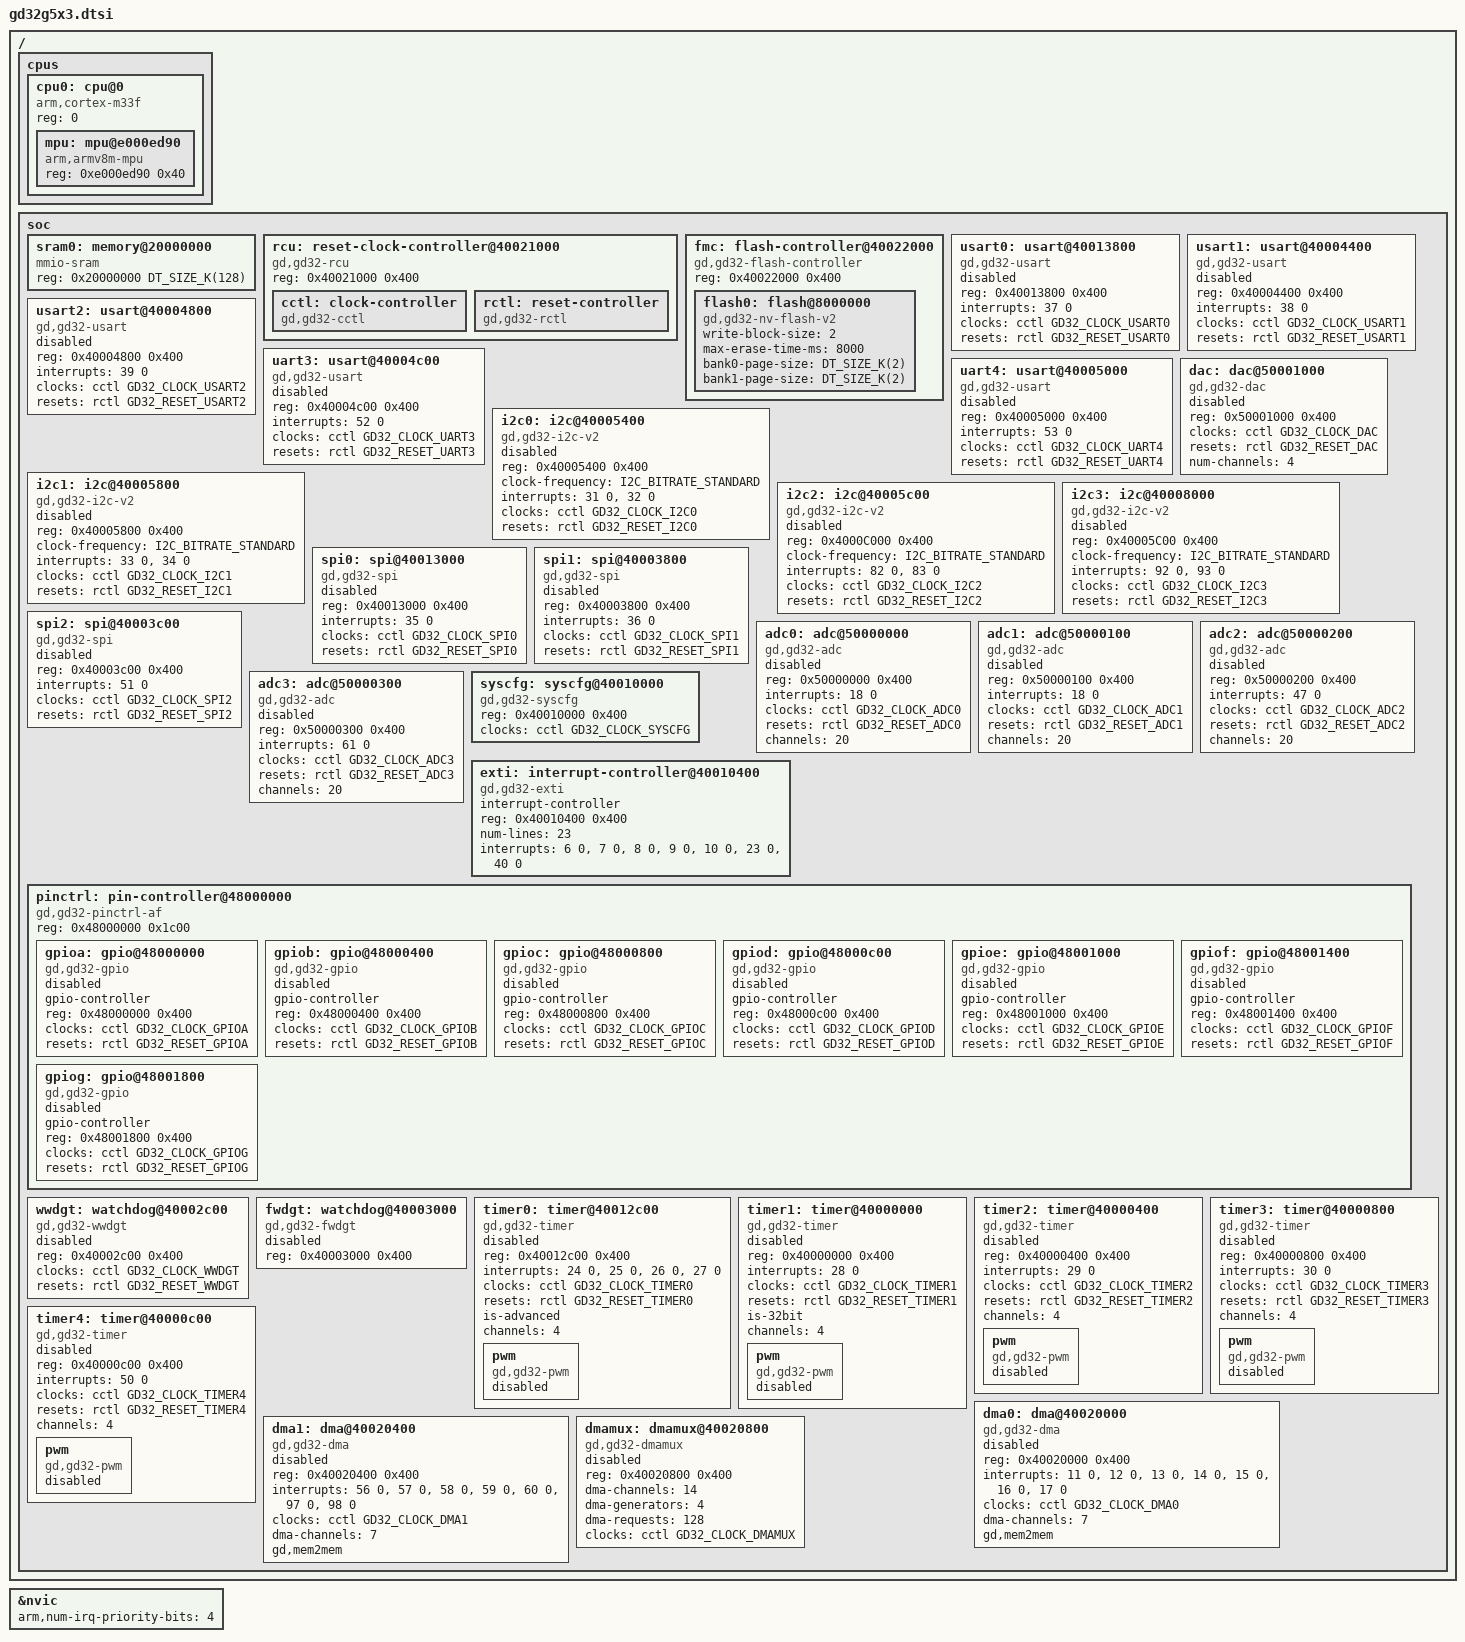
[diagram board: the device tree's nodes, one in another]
/*
 * Copyright (c) 2026 GigaDevice Semiconductor Inc.
 *
 * SPDX-License-Identifier: Apache-2.0
 */

#include <arm/armv8-m.dtsi>
#include <zephyr/dt-bindings/adc/adc.h>
#include <zephyr/dt-bindings/gpio/gpio.h>
#include <zephyr/dt-bindings/i2c/i2c.h>
#include <zephyr/dt-bindings/pwm/pwm.h>
#include <zephyr/dt-bindings/clock/gd32g5x3-clocks.h>
#include <zephyr/dt-bindings/reset/gd32g5x3.h>

/ {
	cpus {
		#address-cells = <1>;
		#size-cells = <0>;

		cpu0: cpu@0 {
			compatible = "arm,cortex-m33f";
			reg = <0>;
			#address-cells = <1>;
			#size-cells = <1>;

			mpu: mpu@e000ed90 {
				compatible = "arm,armv8m-mpu";
				reg = <0xe000ed90 0x40>;
			};
		};
	};

	soc {
		sram0: memory@20000000 {
			compatible = "mmio-sram";
			reg = <0x20000000 DT_SIZE_K(128)>;
		};

		rcu: reset-clock-controller@40021000 {
			compatible = "gd,gd32-rcu";
			reg = <0x40021000 0x400>;
			status = "okay";

			cctl: clock-controller {
				compatible = "gd,gd32-cctl";
				#clock-cells = <1>;
				status = "okay";
			};

			rctl: reset-controller {
				compatible = "gd,gd32-rctl";
				#reset-cells = <1>;
				status = "okay";
			};
		};

		fmc: flash-controller@40022000 {
			compatible = "gd,gd32-flash-controller";
			reg = <0x40022000 0x400>;

			#address-cells = <1>;
			#size-cells = <1>;

			flash0: flash@8000000 {
				compatible = "gd,gd32-nv-flash-v2", "soc-nv-flash";
				write-block-size = <2>;
				max-erase-time-ms = <8000>;
				/* G5x3: dual-bank, page size 2KB in single-bank mode */
				bank0-page-size = <DT_SIZE_K(2)>;
				bank1-page-size = <DT_SIZE_K(2)>;
			};
		};

		usart0: usart@40013800 {
			compatible = "gd,gd32-usart";
			reg = <0x40013800 0x400>;
			interrupts = <37 0>;
			clocks = <&cctl GD32_CLOCK_USART0>;
			resets = <&rctl GD32_RESET_USART0>;
			status = "disabled";
		};

		usart1: usart@40004400 {
			compatible = "gd,gd32-usart";
			reg = <0x40004400 0x400>;
			interrupts = <38 0>;
			clocks = <&cctl GD32_CLOCK_USART1>;
			resets = <&rctl GD32_RESET_USART1>;
			status = "disabled";
		};

		usart2: usart@40004800 {
			compatible = "gd,gd32-usart";
			reg = <0x40004800 0x400>;
			interrupts = <39 0>;
			clocks = <&cctl GD32_CLOCK_USART2>;
			resets = <&rctl GD32_RESET_USART2>;
			status = "disabled";
		};

		uart3: usart@40004c00 {
			compatible = "gd,gd32-usart";
			reg = <0x40004c00 0x400>;
			interrupts = <52 0>;
			clocks = <&cctl GD32_CLOCK_UART3>;
			resets = <&rctl GD32_RESET_UART3>;
			status = "disabled";
		};

		uart4: usart@40005000 {
			compatible = "gd,gd32-usart";
			reg = <0x40005000 0x400>;
			interrupts = <53 0>;
			clocks = <&cctl GD32_CLOCK_UART4>;
			resets = <&rctl GD32_RESET_UART4>;
			status = "disabled";
		};

		dac: dac@50001000 {
			compatible = "gd,gd32-dac";
			reg = <0x50001000 0x400>;
			clocks = <&cctl GD32_CLOCK_DAC>;
			resets = <&rctl GD32_RESET_DAC>;
			num-channels = <4>;
			status = "disabled";
			#io-channel-cells = <1>;
		};

		i2c0: i2c@40005400 {
			compatible = "gd,gd32-i2c-v2";
			reg = <0x40005400 0x400>;
			#address-cells = <1>;
			#size-cells = <0>;
			clock-frequency = <I2C_BITRATE_STANDARD>;
			interrupts = <31 0>, <32 0>;
			interrupt-names = "event", "error";
			clocks = <&cctl GD32_CLOCK_I2C0>;
			resets = <&rctl GD32_RESET_I2C0>;
			status = "disabled";
		};

		i2c1: i2c@40005800 {
			compatible = "gd,gd32-i2c-v2";
			reg = <0x40005800 0x400>;
			#address-cells = <1>;
			#size-cells = <0>;
			clock-frequency = <I2C_BITRATE_STANDARD>;
			interrupts = <33 0>, <34 0>;
			interrupt-names = "event", "error";
			clocks = <&cctl GD32_CLOCK_I2C1>;
			resets = <&rctl GD32_RESET_I2C1>;
			status = "disabled";
		};

		i2c2: i2c@40005c00 {
			compatible = "gd,gd32-i2c-v2";
			reg = <0x4000C000 0x400>;
			#address-cells = <1>;
			#size-cells = <0>;
			clock-frequency = <I2C_BITRATE_STANDARD>;
			interrupts = <82 0>, <83 0>;
			interrupt-names = "event", "error";
			clocks = <&cctl GD32_CLOCK_I2C2>;
			resets = <&rctl GD32_RESET_I2C2>;
			status = "disabled";
		};

		i2c3: i2c@40008000 {
			compatible = "gd,gd32-i2c-v2";
			reg = <0x40005C00 0x400>;
			#address-cells = <1>;
			#size-cells = <0>;
			clock-frequency = <I2C_BITRATE_STANDARD>;
			interrupts = <92 0>, <93 0>;
			interrupt-names = "event", "error";
			clocks = <&cctl GD32_CLOCK_I2C3>;
			resets = <&rctl GD32_RESET_I2C3>;
			status = "disabled";
		};

		spi0: spi@40013000 {
			compatible = "gd,gd32-spi";
			reg = <0x40013000 0x400>;
			interrupts = <35 0>;
			clocks = <&cctl GD32_CLOCK_SPI0>;
			resets = <&rctl GD32_RESET_SPI0>;
			#address-cells = <1>;
			#size-cells = <0>;
			status = "disabled";
		};

		spi1: spi@40003800 {
			compatible = "gd,gd32-spi";
			reg = <0x40003800 0x400>;
			interrupts = <36 0>;
			clocks = <&cctl GD32_CLOCK_SPI1>;
			resets = <&rctl GD32_RESET_SPI1>;
			#address-cells = <1>;
			#size-cells = <0>;
			status = "disabled";
		};

		spi2: spi@40003c00 {
			compatible = "gd,gd32-spi";
			reg = <0x40003c00 0x400>;
			interrupts = <51 0>;
			clocks = <&cctl GD32_CLOCK_SPI2>;
			resets = <&rctl GD32_RESET_SPI2>;
			#address-cells = <1>;
			#size-cells = <0>;
			status = "disabled";
		};

		adc0: adc@50000000 {
			compatible = "gd,gd32-adc";
			reg = <0x50000000 0x400>;
			interrupts = <18 0>;
			clocks = <&cctl GD32_CLOCK_ADC0>;
			resets = <&rctl GD32_RESET_ADC0>;
			channels = <20>;
			#io-channel-cells = <1>;
			status = "disabled";
		};

		adc1: adc@50000100 {
			compatible = "gd,gd32-adc";
			reg = <0x50000100 0x400>;
			interrupts = <18 0>;
			clocks = <&cctl GD32_CLOCK_ADC1>;
			resets = <&rctl GD32_RESET_ADC1>;
			channels = <20>;
			#io-channel-cells = <1>;
			status = "disabled";
		};

		adc2: adc@50000200 {
			compatible = "gd,gd32-adc";
			reg = <0x50000200 0x400>;
			interrupts = <47 0>;
			clocks = <&cctl GD32_CLOCK_ADC2>;
			resets = <&rctl GD32_RESET_ADC2>;
			channels = <20>;
			#io-channel-cells = <1>;
			status = "disabled";
		};

		adc3: adc@50000300 {
			compatible = "gd,gd32-adc";
			reg = <0x50000300 0x400>;
			interrupts = <61 0>;
			clocks = <&cctl GD32_CLOCK_ADC3>;
			resets = <&rctl GD32_RESET_ADC3>;
			channels = <20>;
			#io-channel-cells = <1>;
			status = "disabled";
		};

		syscfg: syscfg@40010000 {
			compatible = "gd,gd32-syscfg";
			reg = <0x40010000 0x400>;
			clocks = <&cctl GD32_CLOCK_SYSCFG>;
		};

		exti: interrupt-controller@40010400 {
			compatible = "gd,gd32-exti";
			interrupt-controller;
			#interrupt-cells = <1>;
			#address-cells = <0>;
			reg = <0x40010400 0x400>;
			num-lines = <23>;
			interrupts = <6 0>, <7 0>, <8 0>, <9 0>,
					<10 0>, <23 0>, <40 0>;
			interrupt-names = "line0", "line1", "line2", "line3",
					"line4", "line5-9", "line10-15";
		};

		pinctrl: pin-controller@48000000 {
			compatible = "gd,gd32-pinctrl-af";
			reg = <0x48000000 0x1c00>;
			#address-cells = <1>;
			#size-cells = <1>;
			status = "okay";

			gpioa: gpio@48000000 {
				compatible = "gd,gd32-gpio";
				gpio-controller;
				#gpio-cells = <2>;
				reg = <0x48000000 0x400>;
				clocks = <&cctl GD32_CLOCK_GPIOA>;
				resets = <&rctl GD32_RESET_GPIOA>;
				status = "disabled";
			};

			gpiob: gpio@48000400 {
				compatible = "gd,gd32-gpio";
				gpio-controller;
				#gpio-cells = <2>;
				reg = <0x48000400 0x400>;
				clocks = <&cctl GD32_CLOCK_GPIOB>;
				resets = <&rctl GD32_RESET_GPIOB>;
				status = "disabled";
			};

			gpioc: gpio@48000800 {
				compatible = "gd,gd32-gpio";
				gpio-controller;
				#gpio-cells = <2>;
				reg = <0x48000800 0x400>;
				clocks = <&cctl GD32_CLOCK_GPIOC>;
				resets = <&rctl GD32_RESET_GPIOC>;
				status = "disabled";
			};

			gpiod: gpio@48000c00 {
				compatible = "gd,gd32-gpio";
				gpio-controller;
				#gpio-cells = <2>;
				reg = <0x48000c00 0x400>;
				clocks = <&cctl GD32_CLOCK_GPIOD>;
				resets = <&rctl GD32_RESET_GPIOD>;
				status = "disabled";
			};

			gpioe: gpio@48001000 {
				compatible = "gd,gd32-gpio";
				gpio-controller;
				#gpio-cells = <2>;
				reg = <0x48001000 0x400>;
				clocks = <&cctl GD32_CLOCK_GPIOE>;
				resets = <&rctl GD32_RESET_GPIOE>;
				status = "disabled";
			};

			gpiof: gpio@48001400 {
				compatible = "gd,gd32-gpio";
				gpio-controller;
				#gpio-cells = <2>;
				reg = <0x48001400 0x400>;
				clocks = <&cctl GD32_CLOCK_GPIOF>;
				resets = <&rctl GD32_RESET_GPIOF>;
				status = "disabled";
			};

			gpiog: gpio@48001800 {
				compatible = "gd,gd32-gpio";
				gpio-controller;
				#gpio-cells = <2>;
				reg = <0x48001800 0x400>;
				clocks = <&cctl GD32_CLOCK_GPIOG>;
				resets = <&rctl GD32_RESET_GPIOG>;
				status = "disabled";
			};
		};

		wwdgt: watchdog@40002c00 {
			compatible = "gd,gd32-wwdgt";
			reg = <0x40002c00 0x400>;
			clocks = <&cctl GD32_CLOCK_WWDGT>;
			resets = <&rctl GD32_RESET_WWDGT>;
			status = "disabled";
		};

		fwdgt: watchdog@40003000 {
			compatible = "gd,gd32-fwdgt";
			reg = <0x40003000 0x400>;
			status = "disabled";
		};

		timer0: timer@40012c00 {
			compatible = "gd,gd32-timer";
			reg = <0x40012c00 0x400>;
			interrupts = <24 0>, <25 0>, <26 0>, <27 0>;
			interrupt-names = "brk", "up", "trgcom", "cc";
			clocks = <&cctl GD32_CLOCK_TIMER0>;
			resets = <&rctl GD32_RESET_TIMER0>;
			is-advanced;
			channels = <4>;
			status = "disabled";

			pwm {
				compatible = "gd,gd32-pwm";
				status = "disabled";
				#pwm-cells = <3>;
			};
		};

		timer1: timer@40000000 {
			compatible = "gd,gd32-timer";
			reg = <0x40000000 0x400>;
			interrupts = <28 0>;
			interrupt-names = "global";
			clocks = <&cctl GD32_CLOCK_TIMER1>;
			resets = <&rctl GD32_RESET_TIMER1>;
			is-32bit;
			channels = <4>;
			status = "disabled";

			pwm {
				compatible = "gd,gd32-pwm";
				status = "disabled";
				#pwm-cells = <3>;
			};
		};

		timer2: timer@40000400 {
			compatible = "gd,gd32-timer";
			reg = <0x40000400 0x400>;
			interrupts = <29 0>;
			interrupt-names = "global";
			clocks = <&cctl GD32_CLOCK_TIMER2>;
			resets = <&rctl GD32_RESET_TIMER2>;
			channels = <4>;
			status = "disabled";

			pwm {
				compatible = "gd,gd32-pwm";
				status = "disabled";
				#pwm-cells = <3>;
			};
		};

		timer3: timer@40000800 {
			compatible = "gd,gd32-timer";
			reg = <0x40000800 0x400>;
			interrupts = <30 0>;
			interrupt-names = "global";
			clocks = <&cctl GD32_CLOCK_TIMER3>;
			resets = <&rctl GD32_RESET_TIMER3>;
			channels = <4>;
			status = "disabled";

			pwm {
				compatible = "gd,gd32-pwm";
				status = "disabled";
				#pwm-cells = <3>;
			};
		};

		timer4: timer@40000c00 {
			compatible = "gd,gd32-timer";
			reg = <0x40000c00 0x400>;
			interrupts = <50 0>;
			interrupt-names = "global";
			clocks = <&cctl GD32_CLOCK_TIMER4>;
			resets = <&rctl GD32_RESET_TIMER4>;
			channels = <4>;
			status = "disabled";

			pwm {
				compatible = "gd,gd32-pwm";
				status = "disabled";
				#pwm-cells = <3>;
			};
		};

		dma0: dma@40020000 {
			compatible = "gd,gd32-dma";
			reg = <0x40020000 0x400>;
			interrupts = <11 0>, <12 0>, <13 0>, <14 0>,
				     <15 0>, <16 0>, <17 0>;
			clocks = <&cctl GD32_CLOCK_DMA0>;
			dma-channels = <7>;
			gd,mem2mem;
			#dma-cells = <2>;
			status = "disabled";
		};

		dma1: dma@40020400 {
			compatible = "gd,gd32-dma";
			reg = <0x40020400 0x400>;
			interrupts = <56 0>, <57 0>, <58 0>, <59 0>,
				     <60 0>, <97 0>, <98 0>;
			clocks = <&cctl GD32_CLOCK_DMA1>;
			dma-channels = <7>;
			gd,mem2mem;
			#dma-cells = <2>;
			status = "disabled";
		};

		dmamux: dmamux@40020800 {
			compatible = "gd,gd32-dmamux";
			reg = <0x40020800 0x400>;
			#dma-cells = <3>;
			dma-channels = <14>;
			dma-generators = <4>;
			dma-requests = <128>;
			clocks = <&cctl GD32_CLOCK_DMAMUX>;
			status = "disabled";
		};
	};
};

&nvic {
	arm,num-irq-priority-bits = <4>;
};
